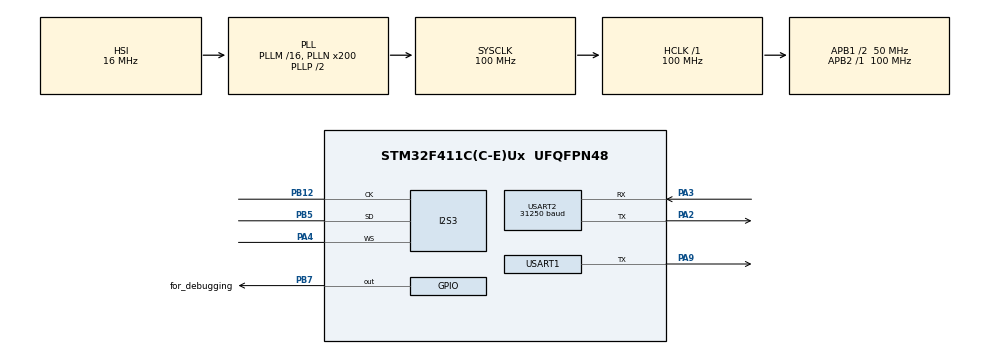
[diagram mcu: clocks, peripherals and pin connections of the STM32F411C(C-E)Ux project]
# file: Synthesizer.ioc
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Dma.Request0=SPI3_TX
Dma.SPI3_TX.0.Direction=DMA_MEMORY_TO_PERIPH
Dma.SPI3_TX.0.FIFOMode=DMA_FIFOMODE_ENABLE
Dma.SPI3_TX.0.FIFOThreshold=DMA_FIFO_THRESHOLD_FULL
Dma.SPI3_TX.0.Instance=DMA1_Stream5
Dma.SPI3_TX.0.MemBurst=DMA_MBURST_SINGLE
Dma.SPI3_TX.0.MemDataAlignment=DMA_MDATAALIGN_WORD
Dma.SPI3_TX.0.MemInc=DMA_MINC_ENABLE
Dma.SPI3_TX.0.Mode=DMA_CIRCULAR
Dma.SPI3_TX.0.PeriphBurst=DMA_PBURST_SINGLE
Dma.SPI3_TX.0.PeriphDataAlignment=DMA_PDATAALIGN_WORD
Dma.SPI3_TX.0.PeriphInc=DMA_PINC_DISABLE
Dma.SPI3_TX.0.Priority=DMA_PRIORITY_HIGH
I2S3.AudioFreq=I2S_AUDIOFREQ_44K
I2S3.DataFormat=I2S_DATAFORMAT_16B_EXTENDED
I2S3.ErrorAudioFreq=-1.35 %
I2S3.FullDuplexMode=I2S_FULLDUPLEXMODE_DISABLE
I2S3.Instance=SPI$Index
I2S3.RealAudioFreq=43.402 KHz
I2S3.VirtualMode=I2S_MODE_MASTER
Mcu.Family=STM32F4
Mcu.Name=STM32F411C(C-E)Ux
Mcu.Package=UFQFPN48
NVIC.DMA1_Stream5_IRQn=true\:0\:0\:false\:false\:true\:false\:true\:true
NVIC.PriorityGroup=NVIC_PRIORITYGROUP_4
NVIC.USART2_IRQn=true\:0\:0\:false\:false\:true\:true\:true\:true
PA2.Mode=Asynchronous
PA2.Signal=USART2_TX
PA3.Mode=Asynchronous
PA3.Signal=USART2_RX
PA4.Mode=Half_Duplex_Master
PA4.Signal=I2S3_WS
PA9.Mode=Half_duplex(single_wire_mode)
PA9.Signal=USART1_TX
PB12.Mode=Half_Duplex_Master
PB12.Signal=I2S3_CK
PB5.Mode=Half_Duplex_Master
PB5.Signal=I2S3_SD
PB7.GPIO_Label=for_debugging
PB7.GPIO_PuPd=GPIO_NOPULL
PB7.GPIO_Speed=GPIO_SPEED_FREQ_LOW
PB7.PinState=GPIO_PIN_RESET
PB7.Signal=GPIO_Output
ProjectManager.HeapSize=0x200
ProjectManager.StackSize=0x400
ProjectManager.TargetToolchain=STM32CubeIDE
RCC.48MHZClocksFreq_Value=50000000
RCC.AHBFreq_Value=100000000
RCC.APB1CLKDivider=RCC_HCLK_DIV2
RCC.APB1Freq_Value=50000000
RCC.APB1TimFreq_Value=100000000
RCC.APB2Freq_Value=100000000
RCC.APB2TimFreq_Value=100000000
RCC.CortexFreq_Value=100000000
RCC.HCLKFreq_Value=100000000
RCC.HSE_VALUE=25000000
RCC.HSI_VALUE=16000000
RCC.LSE_VALUE=32768
RCC.PLLI2SN=200
RCC.PLLN=200
RCC.RCC_MCO1Source=RCC_MCO1SOURCE_PLLCLK
RCC.SYSCLKFreq_VALUE=100000000
RCC.SYSCLKSource=RCC_SYSCLKSOURCE_PLLCLK
RCC.VCOOutputFreq_Value=200000000
USART1.BaudRate=115200
USART1.Mode=MODE_TX
USART1.VirtualMode=VM_ASYNC
USART2.BaudRate=31250
USART2.Mode=MODE_TX_RX
USART2.VirtualMode=VM_ASYNC
board=custom

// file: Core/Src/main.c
/* USER CODE BEGIN Header */
/**
  ******************************************************************************
  * @file           : main.c
  * @brief          : Main program body
  ******************************************************************************
  * @attention
  *
  * Copyright (c) 2025 STMicroelectronics.
  * All rights reserved.
  *
  * This software is licensed under terms that can be found in the LICENSE file
  * in the root directory of this software component.
  * If no LICENSE file comes with this software, it is provided AS-IS.
  *
  ******************************************************************************
  */
/* USER CODE END Header */
#include "main.h"

/* USER CODE BEGIN Includes */
#include "synth.h"
#include "midi.h"
/* USER CODE END Includes */

I2S_HandleTypeDef hi2s3;
DMA_HandleTypeDef hdma_spi3_tx;

UART_HandleTypeDef huart1;
UART_HandleTypeDef huart2;

/* USER CODE BEGIN PV */
uint8_t rx_byte;
uint32_t i2s_tx_buffer[AUDIO_BUFFER_SIZE];

/* USER CODE END PV */

void SystemClock_Config(void);
static void MX_GPIO_Init(void);
static void MX_DMA_Init(void);
static void MX_I2S3_Init(void);
static void MX_USART2_UART_Init(void);
static void MX_USART1_UART_Init(void);

int main(void)
{

  /* MCU Configuration--------------------------------------------------------*/

  /* Reset of all peripherals, Initializes the Flash interface and the Systick. */
  HAL_Init();

  /* Configure the system clock */
  SystemClock_Config();

  /* Initialize all configured peripherals */
  MX_GPIO_Init();
  MX_DMA_Init();
  MX_I2S3_Init();
  MX_USART2_UART_Init();
  MX_USART1_UART_Init();
  /* USER CODE BEGIN 2 */
  synth_init_synth();
  HAL_I2S_Transmit_DMA(&hi2s3, (uint16_t*)i2s_tx_buffer, AUDIO_BUFFER_SIZE);
  HAL_UART_Receive_IT(&huart2, (uint8_t*)&rx_byte, 1);

  /* USER CODE END 2 */

  /* Infinite loop */
  /* USER CODE BEGIN WHILE */

  while (1)
  {
	  // do absolutely nothing!

    /* USER CODE END WHILE */

  }
}

void SystemClock_Config(void)
{
  RCC_OscInitTypeDef RCC_OscInitStruct = {0};
  RCC_ClkInitTypeDef RCC_ClkInitStruct = {0};

  /** Configure the main internal regulator output voltage
  */
  __HAL_RCC_PWR_CLK_ENABLE();
  __HAL_PWR_VOLTAGESCALING_CONFIG(PWR_REGULATOR_VOLTAGE_SCALE1);

  /** Initializes the RCC Oscillators according to the specified parameters
  * in the RCC_OscInitTypeDef structure.
  */
  RCC_OscInitStruct.OscillatorType = RCC_OSCILLATORTYPE_HSI;
  RCC_OscInitStruct.HSIState = RCC_HSI_ON;
  RCC_OscInitStruct.HSICalibrationValue = RCC_HSICALIBRATION_DEFAULT;
  RCC_OscInitStruct.PLL.PLLState = RCC_PLL_ON;
  RCC_OscInitStruct.PLL.PLLSource = RCC_PLLSOURCE_HSI;
  RCC_OscInitStruct.PLL.PLLM = 16;
  RCC_OscInitStruct.PLL.PLLN = 200;
  RCC_OscInitStruct.PLL.PLLP = RCC_PLLP_DIV2;
  RCC_OscInitStruct.PLL.PLLQ = 4;
  if (HAL_RCC_OscConfig(&RCC_OscInitStruct) != HAL_OK)
  {
    Error_Handler();
  }

  /** Initializes the CPU, AHB and APB buses clocks
  */
  RCC_ClkInitStruct.ClockType = RCC_CLOCKTYPE_HCLK|RCC_CLOCKTYPE_SYSCLK
                              |RCC_CLOCKTYPE_PCLK1|RCC_CLOCKTYPE_PCLK2;
  RCC_ClkInitStruct.SYSCLKSource = RCC_SYSCLKSOURCE_PLLCLK;
  RCC_ClkInitStruct.AHBCLKDivider = RCC_SYSCLK_DIV1;
  RCC_ClkInitStruct.APB1CLKDivider = RCC_HCLK_DIV2;
  RCC_ClkInitStruct.APB2CLKDivider = RCC_HCLK_DIV1;

  if (HAL_RCC_ClockConfig(&RCC_ClkInitStruct, FLASH_LATENCY_3) != HAL_OK)
  {
    Error_Handler();
  }
}

static void MX_I2S3_Init(void)
{

  hi2s3.Instance = SPI3;
  hi2s3.Init.Mode = I2S_MODE_MASTER_TX;
  hi2s3.Init.Standard = I2S_STANDARD_PHILIPS;
  hi2s3.Init.DataFormat = I2S_DATAFORMAT_16B_EXTENDED;
  hi2s3.Init.MCLKOutput = I2S_MCLKOUTPUT_DISABLE;
  hi2s3.Init.AudioFreq = I2S_AUDIOFREQ_44K;
  hi2s3.Init.CPOL = I2S_CPOL_LOW;
  hi2s3.Init.ClockSource = I2S_CLOCK_PLL;
  hi2s3.Init.FullDuplexMode = I2S_FULLDUPLEXMODE_DISABLE;
  if (HAL_I2S_Init(&hi2s3) != HAL_OK)
  {
    Error_Handler();
  }

}

static void MX_USART1_UART_Init(void)
{

  huart1.Instance = USART1;
  huart1.Init.BaudRate = 115200;
  huart1.Init.WordLength = UART_WORDLENGTH_8B;
  huart1.Init.StopBits = UART_STOPBITS_1;
  huart1.Init.Parity = UART_PARITY_NONE;
  huart1.Init.Mode = UART_MODE_TX;
  huart1.Init.HwFlowCtl = UART_HWCONTROL_NONE;
  huart1.Init.OverSampling = UART_OVERSAMPLING_16;
  if (HAL_HalfDuplex_Init(&huart1) != HAL_OK)
  {
    Error_Handler();
  }

}

static void MX_USART2_UART_Init(void)
{

  huart2.Instance = USART2;
  huart2.Init.BaudRate = 31250;
  huart2.Init.WordLength = UART_WORDLENGTH_8B;
  huart2.Init.StopBits = UART_STOPBITS_1;
  huart2.Init.Parity = UART_PARITY_NONE;
  huart2.Init.Mode = UART_MODE_TX_RX;
  huart2.Init.HwFlowCtl = UART_HWCONTROL_NONE;
  huart2.Init.OverSampling = UART_OVERSAMPLING_16;
  if (HAL_UART_Init(&huart2) != HAL_OK)
  {
    Error_Handler();
  }

}

static void MX_DMA_Init(void)
{

  /* DMA controller clock enable */
  __HAL_RCC_DMA1_CLK_ENABLE();

  /* DMA interrupt init */
  /* DMA1_Stream5_IRQn interrupt configuration */
  HAL_NVIC_SetPriority(DMA1_Stream5_IRQn, 0, 0);
  HAL_NVIC_EnableIRQ(DMA1_Stream5_IRQn);

}

static void MX_GPIO_Init(void)
{
  GPIO_InitTypeDef GPIO_InitStruct = {0};

  /* GPIO Ports Clock Enable */
  __HAL_RCC_GPIOA_CLK_ENABLE();
  __HAL_RCC_GPIOB_CLK_ENABLE();

  /*Configure GPIO pin Output Level */
  HAL_GPIO_WritePin(for_debugging_GPIO_Port, for_debugging_Pin, GPIO_PIN_RESET);

  /*Configure GPIO pin : for_debugging_Pin */
  GPIO_InitStruct.Pin = for_debugging_Pin;
  GPIO_InitStruct.Mode = GPIO_MODE_OUTPUT_PP;
  GPIO_InitStruct.Pull = GPIO_NOPULL;
  GPIO_InitStruct.Speed = GPIO_SPEED_FREQ_LOW;
  HAL_GPIO_Init(for_debugging_GPIO_Port, &GPIO_InitStruct);

}

void Error_Handler(void)
{
  __disable_irq();
  while (1)
  {
  }
}
